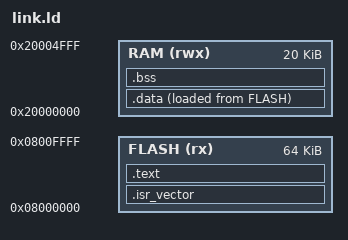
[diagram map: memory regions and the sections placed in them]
/* STM32F103C8 (Blue Pill) — 64 KiB flash, 20 KiB SRAM */
MEMORY
{
  FLASH (rx) : ORIGIN = 0x08000000, LENGTH = 64K
  RAM (rwx)  : ORIGIN = 0x20000000, LENGTH = 20K
}

ENTRY(Reset_Handler)

_estack = ORIGIN(RAM) + LENGTH(RAM);

SECTIONS
{
  .isr_vector : {
    KEEP(*(.isr_vector))
  } > FLASH

  .text : {
    *(.text*)
    *(.text.isr.*)
    *(.rodata*)
    KEEP(*(.init))
    KEEP(*(.fini))
  } > FLASH

  _sidata = LOADADDR(.data);

  .data : {
    _sdata = .;
    *(.data*)
    _edata = .;
  } > RAM AT> FLASH

  .bss : {
    _sbss = .;
    *(.bss*)
    *(COMMON)
    _ebss = .;
  } > RAM
}
